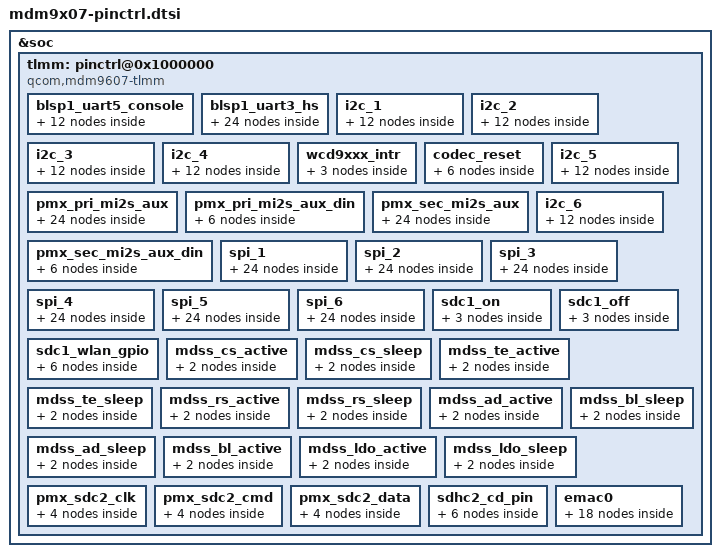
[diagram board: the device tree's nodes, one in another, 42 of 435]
&soc {
	tlmm: pinctrl@0x1000000 {
		compatible = "qcom,mdm9607-tlmm";
		reg = <0x1000000 0x300000>;
		reg-names = "pinctrl";
		interrupts = <0 208 IRQ_TYPE_LEVEL_HIGH>;
		gpio-controller;
		#gpio-cells = <2>;
		interrupt-controller;
		interrupt-parent = <&intc>;
		#interrupt-cells = <2>;
		wakeup-parent = <&wakegic>;

		blsp1_uart5_console: blsp1_uart5_console {
			blsp1_uart5_console_tx5_active: blsp1_uart5_console_tx5_active {
				mux {
					pins = "gpio8";
					function = "blsp_uart_tx5";
				};

				config {
					pins = "gpio8";
					drive-strength = <2>;
					bias-disable;
				};
			};

			blsp1_uart5_console_tx5_sleep: blsp1_uart5_console_tx5_sleep {
				mux {
					pins = "gpio8";
					function = "blsp_uart_tx5";
				};

				config {
					pins = "gpio8";
					drive-strength = <2>;
					bias-pull-up;
				};
			};

			blsp1_uart5_console_rx5_active: blsp1_uart5_console_rx5_active {
				mux {
					pins = "gpio9";
					function = "blsp_uart_rx5";
				};

				config {
					pins = "gpio9";
					drive-strength = <2>;
					bias-disable;
				};
			};

			blsp1_uart5_console_rx5_sleep: blsp1_uart5_console_rx5_sleep {
				mux {
					pins = "gpio9";
					function = "blsp_uart_rx5";
				};

				config {
					pins = "gpio9";
					drive-strength = <2>;
					bias-no-pull;
				};
			};
		};

		blsp1_uart3_hs: blsp1_uart3_hs {
			blsp1_uart3_hs_tx_active: blsp1_uart3_hs_tx_active {
				mux {
					pins = "gpio0";
					function = "blsp_uart_tx3";
				};

				config {
					pins = "gpio0";
					drive-strength = <2>;
					bias-pull-up;
				};
			};

			blsp1_uart3_hs_tx_sleep: blsp1_uart3_hs_tx_sleep {
				mux {
					pins = "gpio0";
					function = "blsp_uart_tx3";
				};

				config {
					pins = "gpio0";
					drive-strength = <2>;
					bias-pull-up;
				};
			};

			blsp1_uart3_hs_rx_active: blsp1_uart3_hs_rx_active {
				mux {
					pins = "gpio1";
					function = "blsp_uart_rx3";
				};

				config {
					pins = "gpio1";
					drive-strength = <2>;
					bias-disable;
				};
			};

			blsp1_uart3_hs_rx_sleep: blsp1_uart3_hs_rx_sleep {
				mux {
					pins = "gpio1";
					function = "gpio";
				};

				config {
					pins = "gpio1";
					drive-strength = <2>;
					bias-pull-down;
				};
			};

			blsp1_uart3_hs_cts_active: blsp1_uart3_hs_cts_active {
				mux {
					pins = "gpio2";
					function = "blsp_uart3";
				};

				config {
					pins = "gpio2";
					drive-strength = <2>;
					bias-disable;
				};
			};

			blsp1_uart3_hs_cts_sleep: blsp1_uart3_hs_cts_sleep {
				mux {
					pins = "gpio2";
					function = "blsp_uart3";
				};

				config {
					pins = "gpio2";
					drive-strength = <2>;
					bias-pull-down;
				};
			};

			blsp1_uart3_hs_rfr_active: blsp1_uart3_hs_rfr_active {
				mux {
					pins = "gpio3";
					function = "blsp_uart3";
				};

				config {
					pins = "gpio3";
					drive-strength = <2>;
					bias-pull-down;
				};
			};

			blsp1_uart3_hs_rfr_sleep: blsp1_uart3_hs_rfr_sleep {
				mux {
					pins = "gpio3";
					function = "blsp_uart3";
				};

				config {
					pins = "gpio3";
					drive-strength = <2>;
					bias-pull-down;
				};
			};
		};

		i2c_1 {
			i2c_1_sda1_active: i2c_1_sda1_active {
				mux {
					pins = "gpio14";
					function = "blsp_i2c_sda1";
				};

				config {
					pins = "gpio14";
					drive-strength = <2>;
					bias-pull-up;
				};
			};

			i2c_1_sda1_sleep: i2c_1_sda1_sleep {
				mux {
					pins = "gpio14";
					function = "blsp_i2c_sda1";
				};

				config {
					pins = "gpio14";
					drive-strength = <2>;
					bias-disable;
				};
			};

			i2c_1_scl1_active: i2c_1_scl1_active {
				mux {
					pins = "gpio15";
					function = "blsp_i2c_scl1";
				};

				config {
					pins = "gpio15";
					drive-strength = <2>;
					bias-pull-up;
				};
			};

			i2c_1_scl1_sleep: i2c_1_scl1_sleep {
				mux {
					pins = "gpio15";
					function = "blsp_i2c_scl1";
				};

				config {
					pins = "gpio15";
					drive-strength = <2>;
					bias-disable;
				};
			};
		};

		i2c_2 {
			i2c_2_sda2_active: i2c_2_sda2_active {
				mux {
					pins = "gpio6";
					function = "blsp_i2c_sda2";
				};

				config {
					pins = "gpio6";
					drive-strength = <2>;
					bias-pull-up;
				};
			};

			i2c_2_sda2_sleep: i2c_2_sda2_sleep {
				mux {
					pins = "gpio6";
					function = "blsp_i2c_sda2";
				};

				config {
					pins = "gpio6";
					drive-strength = <2>;
					bias-disable;
				};
			};

			i2c_2_scl2_active: i2c_2_scl2_active {
				mux {
					pins = "gpio7";
					function = "blsp_i2c_scl2";
				};

				config {
					pins = "gpio7";
					drive-strength = <2>;
					bias-pull-up;
				};
			};

			i2c_2_scl2_sleep: i2c_2_scl2_sleep {
				mux {
					pins = "gpio7";
					function = "blsp_i2c_scl2";
				};

				config {
					pins = "gpio7";
					drive-strength = <2>;
					bias-disable;
				};
			};
		};

		i2c_3 {
			i2c_3_sda3_active: i2c_3_sda3_active {
				mux {
					pins = "gpio2";
					function = "blsp_i2c_sda3";
				};

				config {
					pins = "gpio2";
					drive-strength = <2>;
					bias-pull-up;
				};
			};

			i2c_3_sda3_sleep: i2c_3_sda3_sleep {
				mux {
					pins = "gpio2";
					function = "blsp_i2c_sda3";
				};

				config {
					pins = "gpio2";
					drive-strength = <2>;
					bias-disable;
				};
			};

			i2c_3_scl3_active: i2c_3_scl3_active {
				mux {
					pins = "gpio3";
					function = "blsp_i2c_scl3";
				};

				config {
					pins = "gpio3";
					drive-strength = <2>;
					bias-pull-up;
				};
			};

			i2c_3_scl3_sleep: i2c_3_scl3_sleep {
				mux {
					pins = "gpio3";
					function = "blsp_i2c_scl3";
				};

				config {
					pins = "gpio3";
					drive-strength = <2>;
					bias-disable;
				};
			};
		};

		i2c_4 {
			i2c_4_sda4_active: i2c_4_sda4_active {
				mux {
					pins = "gpio18";
					function = "blsp_i2c_sda4";
				};

				config {
					pins = "gpio18";
					drive-strength = <2>;
					bias-pull-up;
				};
			};

			i2c_4_sda4_sleep: i2c_4_sda4_sleep {
				mux {
					pins = "gpio18";
					function = "blsp_i2c_sda4";
				};

				config {
					pins = "gpio18";
					drive-strength = <2>;
					bias-disable;
				};
			};

			i2c_4_scl4_active: i2c_4_scl4_active {
				mux {
					pins = "gpio19";
					function = "blsp_i2c_scl4";
				};

				config {
					pins = "gpio19";
					drive-strength = <2>;
					bias-pull-up;
				};
			};

			i2c_4_scl4_sleep: i2c_4_scl4_sleep {
				mux {
					pins = "gpio19";
					function = "blsp_i2c_scl4";
				};

				config {
					pins = "gpio19";
					drive-strength = <2>;
					bias-disable;
				};
			};
		};

		wcd9xxx_intr {
			wcd_intr_default: wcd_intr_default {
				mux {
					pins = "gpio75";
					function = "gpio";
				};

				config {
					pins = "gpio75";
					drive-strength = <2>; /* 2 mA */
					bias-pull-down; /* pull down */
					input-enable;
				};
			};
		};

		codec_reset {
			codec_reset_active: codec_reset_active {
				mux {
					pins = "gpio26";
					function = "gpio";
				};

				config {
					pins = "gpio26";
					drive-strength = <8>;   /* 8 MA */
					bias-disable;           /* No PULL */
					output-high;
				};
			};

			codec_reset_sleep: codec_reset_sleep {
				mux {
					pins = "gpio26";
					function = "gpio";
				};

				config {
					pins = "gpio26";
					drive-strength = <2>;   /* 2 MA */
					bias-pull-down;	        /* PULL DOWN */
				};
			};
		};

		pmx_pri_mi2s_aux {
			pri_ws_active_master: pri_ws_active_master {
				mux {
					pins = "gpio20";
					function = "pri_mi2s_ws_a";
				};

				config {
					pins = "gpio20";
					drive-strength = <8>;   /* 8 MA */
					bias-disable;           /* No PULL */
					output-high;
				};
			};

			pri_sck_active_master: pri_sck_active_master {
				mux {
					pins = "gpio23";
					function = "pri_mi2s_sck_a";
				};

				config {
					pins = "gpio23";
					drive-strength = <8>;   /* 8 MA */
					bias-disable;           /* No PULL */
					output-high;
				};
			};

			pri_ws_active_slave: pri_ws_active_slave {
				mux {
					pins = "gpio20";
					function = "pri_mi2s_ws_a";
				};

				config {
					pins = "gpio20";
					drive-strength = <8>;   /* 8 MA */
					bias-disable;           /* No PULL */
				};
			};

			pri_sck_active_slave: pri_sck_active_slave {
				mux {
					pins = "gpio23";
					function = "pri_mi2s_sck_a";
				};

				config {
					pins = "gpio23";
					drive-strength = <8>;   /* 8 MA */
					bias-disable;           /* No PULL */
				};
			};

			pri_dout_active: pri_dout_active {
				mux {
					pins = "gpio22";
					function = "pri_mi2s_data1_a";
				};

				config {
					pins = "gpio22";
					drive-strength = <8>;   /* 8 MA */
					bias-disable;           /* No PULL */
					output-high;
				};
			};

			pri_ws_sleep: pri_ws_sleep {
				mux {
					pins = "gpio20";
					function = "pri_mi2s_ws_a";
				};

				config {
					pins = "gpio20";
					drive-strength = <2>;   /* 2 MA */
					bias-pull-down;	        /* PULL DOWN */
				};
			};

			pri_sck_sleep: pri_sck_sleep {
				mux {
					pins = "gpio23";
					function = "pri_mi2s_sck_a";
				};

				config {
					pins = "gpio23";
					drive-strength = <2>;   /* 2 MA */
					bias-pull-down;	        /* PULL DOWN */
				};
			};

			pri_dout_sleep: pri_dout_sleep {
				mux {
					pins = "gpio22";
					function = "pri_mi2s_data1_a";
				};

				config {
					pins = "gpio22";
					drive-strength = <2>;   /* 2 MA */
					bias-pull-down;	        /* PULL DOWN */
				};
			};
		};

		pmx_pri_mi2s_aux_din {
				pri_din_active: pri_din_active {
				mux {
					pins = "gpio21";
					function = "pri_mi2s_data0_a";
				};

				config {
					pins = "gpio21";
					drive-strength = <8>;   /* 8 MA */
					bias-disable;	        /* No PULL */
				};
			};

			pri_din_sleep: pri_din_sleep {
				mux {
					pins = "gpio21";
					function = "pri_mi2s_data0_a";
				};

				config {
					pins = "gpio21";
					drive-strength = <2>;   /* 2 MA */
					bias-pull-down;	        /* PULL DOWN */
				};
			};
		};

		pmx_sec_mi2s_aux {
			sec_ws_active_master: sec_ws_active_master {
				mux {
					pins = "gpio79";
					function = "sec_mi2s_ws";
				};

				config {
					pins = "gpio79";
					drive-strength = <8>;   /* 8 MA */
					bias-disable;           /* No PULL */
					output-high;
				};
			};

			sec_sck_active_master: sec_sck_active_master {
				mux {
					pins = "gpio78";
					function = "sec_mi2s_sck";
				};

				config {
					pins = "gpio78";
					drive-strength = <8>;   /* 8 MA */
					bias-disable;           /* No PULL */
					output-high;
				};
			};

			sec_ws_active_slave: sec_ws_active_slave {
				mux {
					pins = "gpio79";
					function = "sec_mi2s_ws";
				};

				config {
					pins = "gpio79";
					drive-strength = <8>;   /* 8 MA */
					bias-disable;           /* No PULL */
				};
			};

			sec_sck_active_slave: sec_sck_active_slave {
				mux {
					pins = "gpio78";
					function = "sec_mi2s_sck";
				};

				config {
					pins = "gpio78";
					drive-strength = <8>;   /* 8 MA */
					bias-disable;           /* No PULL */
				};
			};

			sec_dout_active: sec_dout_active {
				mux {
					pins = "gpio77";
					function = "sec_mi2s_data1";
				};

				config {
					pins = "gpio77";
					drive-strength = <8>;   /* 8 MA */
					bias-disable;           /* No PULL */
					output-high;
				};
			};

			sec_ws_sleep: sec_ws_sleep {
				mux {
					pins = "gpio79";
					function = "sec_mi2s_ws";
				};

				config {
					pins = "gpio79";
					drive-strength = <2>;   /* 2 MA */
					bias-pull-down;	        /* PULL DOWN */
				};
			};

			sec_sck_sleep: sec_sck_sleep {
				mux {
					pins = "gpio78";
					function = "sec_mi2s_sck";
				};

				config {
					pins = "gpio78";
					drive-strength = <2>;   /* 2 MA */
					bias-pull-down;	        /* PULL DOWN */
				};
			};

			sec_dout_sleep: sec_dout_sleep {
				mux {
					pins = "gpio77";
					function = "sec_mi2s_data1";
				};

				config {
					pins = "gpio77";
					drive-strength = <2>;   /* 2 MA */
					bias-pull-down;	        /* PULL DOWN */
				};
			};
		};

		pmx_sec_mi2s_aux_din {
			sec_din_active: sec_din_active {
				mux {
					pins = "gpio76";
					function = "sec_mi2s_data0";
				};

				config {
					pins = "gpio76";
					drive-strength = <8>;   /* 8 MA */
					bias-disable;	        /* No PULL */
				};
			};

			sec_din_sleep: sec_din_sleep {
				mux {
					pins = "gpio76";
					function = "sec_mi2s_data0";
				};

				config {
					pins = "gpio76";
					drive-strength = <2>;   /* 2 MA */
					bias-pull-down;	        /* PULL DOWN */
				};
			};
		};

		i2c_5 {
			i2c_5_sda5_active: i2c_5_sda5_active {
				mux {
					pins = "gpio10";
					function = "blsp_i2c_sda5";
				};

				config {
					pins = "gpio10";
					drive-strength = <2>;
					bias-pull-up;
				};
			};

			i2c_5_sda5_sleep: i2c_5_sda5_sleep {
				mux {
					pins = "gpio10";
					function = "blsp_i2c_sda5";
				};

				config {
					pins = "gpio10";
					drive-strength = <2>;
					bias-disable;
				};
			};

			i2c_5_scl5_active: i2c_5_scl5_active {
				mux {
					pins = "gpio11";
					function = "blsp_i2c_scl5";
				};

				config {
					pins = "gpio11";
					drive-strength = <2>;
					bias-pull-up;
				};
			};

			i2c_5_scl5_sleep: i2c_5_scl5_sleep {
				mux {
					pins = "gpio11";
					function = "blsp_i2c_scl5";
				};

				config {
					pins = "gpio11";
					drive-strength = <2>;
					bias-disable;
				};
			};
		};

		i2c_6 {
			i2c_6_sda6_active: i2c_6_sda6_active {
				mux {
					pins = "gpio22";
					function = "blsp_i2c_sda6";
				};

				config {
					pins = "gpio22";
					drive-strength = <2>;
					bias-pull-up;
				};
			};

			i2c_6_sda6_sleep: i2c_6_sda6_sleep {
				mux {
					pins = "gpio22";
					function = "blsp_i2c_sda6";
				};

				config {
					pins = "gpio22";
					drive-strength = <2>;
					bias-disable;
				};
			};

			i2c_6_scl6_active: i2c_6_scl6_active {
				mux {
					pins = "gpio23";
					function = "blsp_i2c_scl6";
				};

				config {
					pins = "gpio23";
					drive-strength = <2>;
					bias-pull-up;
				};
			};

			i2c_6_scl6_sleep: i2c_6_scl6_sleep {
				mux {
					pins = "gpio23";
					function = "blsp_i2c_scl6";
				};

				config {
					pins = "gpio23";
					drive-strength = <2>;
					bias-disable;
				};
			};
		};

		spi_1 {
			spi_1_mosi1_default: spi_1_mosi1_default {
				mux {
					pins = "gpio12";
					function = "blsp_spi_mosi1";
				};

				config {
					pins = "gpio12";
					drive-strength = <12>;
					bias-disable;
				};
			};

			spi_1_mosi1_sleep: spi_1_mosi1_sleep {
				mux {
					pins = "gpio12";
					function = "blsp_spi_mosi1";
				};

				config {
					pins = "gpio12";
					drive-strength = <2>;
					bias-pull-down;
				};
			};

			spi_1_miso1_default: spi_1_miso1_default {
				mux {
					pins = "gpio13";
					function = "blsp_spi_miso1";
				};

				config {
					pins = "gpio13";
					drive-strength = <12>;
					bias-disable;
				};
			};

			spi_1_miso1_sleep: spi_1_miso1_sleep {
				mux {
					pins = "gpio13";
					function = "blsp_spi_miso1";
				};

				config {
					pins = "gpio13";
					drive-strength = <2>;
					bias-pull-down;
				};
			};

			spi_1_cs1_active: spi_1_cs1_active {
				mux {
					pins = "gpio14";
					function = "blsp_spi1";
				};

				config {
					pins = "gpio14";
					drive-strength = <2>;
					bias-disable;
				};
			};

			spi_1_cs1_sleep: spi_1_cs1_sleep {
				mux {
					pins = "gpio14";
					function = "blsp_spi1";
				};

				config {
					pins = "gpio14";
					drive-strength = <2>;
					bias-pull-down;
				};
			};

			spi_1_clk1_default: spi_1_clk1_default {
				mux {
					pins = "gpio15";
					function = "blsp_spi_clk1";
				};

				config {
					pins = "gpio15";
					drive-strength = <12>;
					bias-disable;
				};
			};

			spi_1_clk1_sleep: spi_1_clk1_sleep {
				mux {
					pins = "gpio15";
					function = "blsp_spi_clk1";
				};

				config {
					pins = "gpio15";
					drive-strength = <2>;
					bias-pull-down;
				};
			};
		};

		spi_2 {
			spi_2_mosi2_default: spi_2_mosi2_default {
				mux {
					pins = "gpio4";
					function = "blsp_spi_mosi2";
				};

				config {
					pins = "gpio4";
					drive-strength = <12>;
					bias-disable;
				};
			};

			spi_2_mosi2_sleep: spi_2_mosi2_sleep {
				mux {
					pins = "gpio4";
					function = "blsp_spi_mosi2";
				};

				config {
					pins = "gpio4";
					drive-strength = <2>;
					bias-pull-down;
				};
			};

			spi_2_miso2_default: spi_2_miso2_default {
				mux {
					pins = "gpio5";
					function = "blsp_spi_miso2";
				};

				config {
					pins = "gpio5";
					drive-strength = <12>;
					bias-disable;
				};
			};

			spi_2_miso2_sleep: spi_2_miso2_sleep {
				mux {
					pins = "gpio5";
					function = "blsp_spi_miso2";
				};

				config {
					pins = "gpio5";
					drive-strength = <2>;
					bias-pull-down;
				};
			};

			spi_2_cs2_active: spi_2_cs2_active {
				mux {
					pins = "gpio6";
					function = "blsp_spi2";
				};

				config {
					pins = "gpio6";
					drive-strength = <2>;
					bias-disable;
				};
			};

			spi_2_cs2_sleep: spi_2_cs2_sleep {
				mux {
					pins = "gpio6";
					function = "blsp_spi2";
				};

				config {
					pins = "gpio6";
					drive-strength = <2>;
					bias-pull-down;
				};
			};

			spi_2_clk2_default: spi_2_clk2_default {
				mux {
					pins = "gpio7";
					function = "blsp_spi_clk2";
				};

				config {
					pins = "gpio7";
					drive-strength = <12>;
					bias-disable;
				};
			};

			spi_2_clk2_sleep: spi_2_clk2_sleep {
				mux {
					pins = "gpio7";
					function = "blsp_spi_clk2";
				};

				config {
					pins = "gpio7";
					drive-strength = <2>;
					bias-pull-down;
				};
			};
		};

		spi_3 {
			spi_3_mosi3_default: spi_3_mosi3_default {
				mux {
					pins = "gpio0";
					function = "blsp_spi_mosi3";
				};

				config {
					pins = "gpio0";
					drive-strength = <12>;
					bias-disable;
				};
			};

			spi_3_mosi3_sleep: spi_3_mosi3_sleep {
				mux {
					pins = "gpio0";
					function = "blsp_spi_mosi3";
				};

				config {
					pins = "gpio0";
					drive-strength = <2>;
					bias-pull-down;
				};
			};

			spi_3_miso3_default: spi_3_miso3_default {
				mux {
					pins = "gpio1";
					function = "blsp_spi_miso3";
				};

				config {
					pins = "gpio1";
					drive-strength = <12>;
					bias-disable;
				};
			};

			spi_3_miso3_sleep: spi_3_miso3_sleep {
				mux {
					pins = "gpio1";
					function = "blsp_spi_miso3";
				};

				config {
					pins = "gpio1";
					drive-strength = <2>;
					bias-pull-down;
				};
			};

			spi_3_cs3_active: spi_3_cs3_active {
				mux {
					pins = "gpio2";
					function = "blsp_spi3";
				};

				config {
					pins = "gpio2";
					drive-strength = <2>;
					bias-disable;
				};
			};

			spi_3_cs3_sleep: spi_3_cs3_sleep {
				mux {
					pins = "gpio2";
					function = "blsp_spi3";
				};

				config {
					pins = "gpio2";
					drive-strength = <2>;
					bias-pull-down;
				};
			};

			spi_3_clk3_default: spi_3_clk3_default {
				mux {
					pins = "gpio3";
					function = "blsp_spi_clk3";
				};

				config {
					pins = "gpio3";
					drive-strength = <12>;
					bias-disable;
				};
			};

			spi_3_clk3_sleep: spi_3_clk3_sleep {
				mux {
					pins = "gpio3";
					function = "blsp_spi_clk3";
				};

				config {
					pins = "gpio3";
					drive-strength = <2>;
					bias-pull-down;
				};
			};
		};

		spi_4 {
			spi_4_mosi4_default: spi_4_mosi4_default {
				mux {
					pins = "gpio16";
					function = "blsp_spi_mosi4";
				};

				config {
					pins = "gpio16";
					drive-strength = <12>;
					bias-disable;
				};
			};

			spi_4_mosi4_sleep: spi_4_mosi4_sleep {
				mux {
					pins = "gpio16";
					function = "blsp_spi_mosi4";
				};

				config {
					pins = "gpio16";
					drive-strength = <2>;
					bias-pull-down;
				};
			};

			spi_4_miso4_default: spi_4_miso4_default {
				mux {
					pins = "gpio17";
					function = "blsp_spi_miso4";
				};

				config {
					pins = "gpio17";
					drive-strength = <12>;
					bias-disable;
				};
			};

			spi_4_miso4_sleep: spi_4_miso4_sleep {
				mux {
					pins = "gpio17";
					function = "blsp_spi_miso4";
				};

				config {
					pins = "gpio17";
					drive-strength = <2>;
					bias-pull-down;
				};
			};

			spi_4_cs4_active: spi_4_cs4_active {
				mux {
					pins = "gpio18";
					function = "blsp_spi4";
				};

				config {
					pins = "gpio18";
					drive-strength = <2>;
					bias-disable;
				};
			};

			spi_4_cs4_sleep: spi_4_cs4_sleep {
				mux {
					pins = "gpio18";
					function = "blsp_spi4";
				};

				config {
					pins = "gpio18";
					drive-strength = <2>;
					bias-pull-down;
				};
			};

			spi_4_clk4_default: spi_4_clk4_default {
				mux {
					pins = "gpio19";
					function = "blsp_spi_clk4";
				};

				config {
					pins = "gpio19";
					drive-strength = <12>;
					bias-disable;
				};
			};

			spi_4_clk4_sleep: spi_4_clk4_sleep {
				mux {
					pins = "gpio19";
					function = "blsp_spi_clk4";
				};

				config {
					pins = "gpio19";
					drive-strength = <2>;
					bias-pull-down;
				};
			};
		};

		spi_5 {
			spi_5_mosi5_default: spi_5_mosi5_default {
				mux {
					pins = "gpio8";
					function = "blsp_spi_mosi5";
				};

				config {
					pins = "gpio8";
					drive-strength = <12>;
					bias-disable;
				};
			};

			spi_5_mosi5_sleep: spi_5_mosi5_sleep {
				mux {
					pins = "gpio8";
					function = "blsp_spi_mosi5";
				};

				config {
					pins = "gpio8";
					drive-strength = <2>;
					bias-pull-down;
				};
			};

			spi_5_miso5_default: spi_5_miso5_default {
				mux {
					pins = "gpio9";
					function = "blsp_spi_miso5";
				};

				config {
					pins = "gpio9";
					drive-strength = <12>;
					bias-disable;
				};
			};

			spi_5_miso5_sleep: spi_5_miso5_sleep {
				mux {
					pins = "gpio9";
					function = "blsp_spi_miso5";
				};

				config {
					pins = "gpio9";
					drive-strength = <2>;
					bias-pull-down;
				};
			};

			spi_5_cs5_active: spi_5_cs5_active {
				mux {
					pins = "gpio10";
					function = "blsp_spi5";
				};

				config {
					pins = "gpio10";
					drive-strength = <2>;
					bias-disable;
				};
			};

			spi_5_cs5_sleep: spi_5_cs5_sleep {
				mux {
					pins = "gpio10";
					function = "blsp_spi5";
				};

				config {
					pins = "gpio10";
					drive-strength = <2>;
					bias-pull-down;
				};
			};

			spi_5_clk5_default: spi_5_clk5_default {
				mux {
					pins = "gpio11";
					function = "blsp_spi_clk5";
				};

				config {
					pins = "gpio11";
					drive-strength = <12>;
					bias-disable;
				};
			};

			spi_5_clk5_sleep: spi_5_clk5_sleep {
				mux {
					pins = "gpio11";
					function = "blsp_spi_clk5";
				};

				config {
					pins = "gpio11";
					drive-strength = <2>;
					bias-pull-down;
				};
			};
		};

		spi_6 {
			spi_6_mosi6_default: spi_6_mosi6_default {
				mux {
					pins = "gpio20";
					function = "blsp_spi_mosi6";
				};

				config {
					pins = "gpio20";
					drive-strength = <12>;
					bias-disable;
				};
			};

			spi_6_mosi6_sleep: spi_6_mosi6_sleep {
				mux {
					pins = "gpio20";
					function = "blsp_spi_mosi6";
				};

				config {
					pins = "gpio20";
					drive-strength = <2>;
					bias-pull-down;
				};
			};

			spi_6_miso6_default: spi_6_miso6_default {
				mux {
					pins = "gpio21";
					function = "blsp_spi_miso6";
				};

				config {
					pins = "gpio21";
					drive-strength = <12>;
					bias-disable;
				};
			};

			spi_6_miso6_sleep: spi_6_miso6_sleep {
				mux {
					pins = "gpio21";
					function = "blsp_spi_miso6";
				};

				config {
					pins = "gpio21";
					drive-strength = <2>;
					bias-pull-down;
				};
			};

			spi_6_cs6_active: spi_6_cs6_active {
				mux {
					pins = "gpio22";
					function = "blsp_spi6";
				};

				config {
					pins = "gpio22";
					drive-strength = <2>;
					bias-disable;
				};
			};

			spi_6_cs6_sleep: spi_6_cs6_sleep {
				mux {
					pins = "gpio22";
					function = "blsp_spi6";
				};

				config {
					pins = "gpio22";
					drive-strength = <2>;
					bias-pull-down;
				};
			};

			spi_6_clk6_default: spi_6_clk6_default {
				mux {
					pins = "gpio23";
					function = "blsp_spi_clk6";
				};

				config {
					pins = "gpio23";
					drive-strength = <12>;
					bias-disable;
				};
			};

			spi_6_clk6_sleep: spi_6_clk6_sleep {
				mux {
					pins = "gpio23";
					function = "blsp_spi_clk6";
				};

				config {
					pins = "gpio23";
					drive-strength = <2>;
					bias-pull-down;
				};
			};
		};

		/* SDC pin type */


		sdc1_on: sdc1_on {
			clk {
				pins = "sdc1_clk";
				bias-disable;
				drive-strength = <16>;
			};

			cmd {
				pins = "sdc1_cmd";
				bias-pull-up;
				drive-strength = <10>;
			};

			data {
				pins = "sdc1_data";
				bias-pull-up;
				drive-strength = <10>;
			};
		};

		sdc1_off: sdc1_off {
			clk {
				pins = "sdc1_clk";
				bias-disable;
				drive-strength = <2>;
			};

			cmd {
				pins = "sdc1_cmd";
				bias-pull-up;
				drive-strength = <2>;
			};

			data {
				pins = "sdc1_data";
				bias-pull-up;
				drive-strength = <2>;
			};
		};

		sdc1_wlan_gpio {
			sdc1_wlan_gpio_active: sdc1_wlan_gpio_active {
				mux {
					pins = "gpio38";
					function  = "gpio";
				};

				config {
					pins  = "gpio38";
					output-high;
					drive-strength = <8>;
					bias-pull-up;
				};
			};

			sdc1_wlan_gpio_sleep: sdc1_wlan_gpio_sleep {
				mux {
					pins = "gpio38";
					function  = "gpio";
				};

				config {
					pins  = "gpio38";
					drive-strength = <2>;
					bias-disable;
					output-low;
				};
			};
		};

		mdss_cs_active: mdss_cs_active {
			mux {
				pins = "gpio23";
				function = "ebi2_lcd_cs_n_b";
			};

			config {
				pins = "gpio23";
				drive-strength = <10>;/*10mA*/
				bias-disable;/*NOpull*/
			};
		};

		mdss_cs_sleep:mdss_cs_sleep {
			mux {
				pins = "gpio23";
				function = "ebi2_lcd_cs_n_b";
			};

			config {
				pins = "gpio23";
				drive-strength = <2>;/*2mA*/
				bias-disable;/*NOpull*/
			};
		};

		mdss_te_active:mdss_te_active {
			mux {
				pins = "gpio20";
				function = "ebi2_lcd_te_b";
			};

			config {
				pins = "gpio20";
				drive-strength = <10>;/*10mA*/
				bias-disable;/*NOpull*/
			};
		};

		mdss_te_sleep:mdss_te_sleep {
			mux {
				pins = "gpio20";
				function = "ebi2_lcd_te_b";
			};

			config {
				pins = "gpio20";
				drive-strength = <2>;/*2mA*/
				bias-disable;/*NOpull*/
			};
		};

		mdss_rs_active:mdss_rs_active {
			mux {
				pins = "gpio74";
				function = "ebi2_lcd";
			};

			config {
				pins = "gpio74";
				drive-strength = <10>;/*10mA*/
				bias-disable;/*NOpull*/
			};
		};

		mdss_rs_sleep:mdss_rs_sleep {
			mux {
				pins = "gpio74";
				function = "ebi2_lcd";
			};

			config {
				pins = "gpio74";
				drive-strength = <2>;/*2mA*/
				bias-disable;/*NOpull*/
			};
		};

		mdss_ad_active:mdss_ad_active {
			mux {
				pins = "gpio22";
				function = "ebi2_a_d_8_b";
			};

			config {
				pins = "gpio22";
				drive-strength = <10>;/*10mA*/
				bias-disable;/*NOpull*/
			};
		};

		mdss_ad_sleep:mdss_ad_sleep {
			mux {
				pins = "gpio22";
				function = "ebi2_a_d_8_b";
			};

			config {
				pins = "gpio22";
				drive-strength = <2>;/*2mA*/
				bias-disable;/*NOpull*/
			};
		};

		mdss_bl_active:mdss_bl_active {
			mux {
				pins = "gpio21";
				function = "gpio";
			};

			config {
				pins = "gpio21";
				drive-strength = <10>;/*10mA*/
				bias-disable;/*NOpull*/
				output-high;
			};
		};

		mdss_bl_sleep:mdss_bl_sleep {
			mux {
				pins = "gpio21";
				function = "gpio";
			};

			config {
				pins = "gpio21";
				drive-strength = <2>;/*2mA*/
				bias-disable;/*NOpull*/
			};
		};

		mdss_ldo_active:mdss_ldo_active {
			mux {
				pins = "gpio10";
				function = "gpio";
			};

			config {
				pins = "gpio10";
				drive-strength = <10>;/*10mA*/
				bias-disable;/*NOpull*/
				output-high;
			};
		};

		mdss_ldo_sleep:mdss_ldo_sleep {
			mux {
				pins = "gpio10";
				function = "gpio";
			};

			config {
				pins = "gpio10";
				drive-strength = <2>;/*2mA*/
				bias-disable;/*NOpull*/
				output-low;
			};
		};

		pmx_sdc2_clk {
			sdc2_clk_on: sdc2_clk_on {
				config {
					pins = "sdc2_clk";
					drive-strength = <16>; /* 16 MA */
					bias-disable; /* NO pull */
				};
			};

			sdc2_clk_off: sdc2_clk_off {
				config {
					pins = "sdc2_clk";
					bias-disable; /* NO pull */
					drive-strength = <2>; /* 2 MA */
				};
			};
		};

		pmx_sdc2_cmd {
			sdc2_cmd_on: sdc2_cmd_on {
				config {
					pins = "sdc2_cmd";
					bias-pull-up; /* pull up */
					drive-strength = <10>; /* 10 MA */
				};
			};

			sdc2_cmd_off: sdc2_cmd_off {
				config {
					pins = "sdc2_cmd";
					bias-pull-up; /* pull up */
					drive-strength = <2>; /* 2 MA */
				};
			};
		};

		pmx_sdc2_data {
			sdc2_data_on: sdc2_data_on {
				config {
					pins = "sdc2_data";
					bias-pull-up; /* pull up */
					drive-strength = <10>; /* 10 MA */
				};
			};

			sdc2_data_off: sdc2_data_off {
				config {
					pins = "sdc2_data";
					bias-pull-up; /* pull up */
					drive-strength = <2>; /* 2 MA */
				};
			};
		};

		sdhc2_cd_pin {
			sdc2_cd_on: cd_on {
				mux {
					pins = "gpio26";
					function = "gpio";
				};

				config {
					pins = "gpio26";
					drive-strength = <2>;
					bias-pull-up;
				};
			};

			sdc2_cd_off: cd_off {
				mux {
					pins = "gpio26";
					function = "gpio";
				};

				config {
					pins = "gpio26";
					drive-strength = <2>;
					bias-disable;
				};
			};
		};

		emac0 {
			emac0_mdio_clk_active: emac0_mdio_clk_active {
				/* active state */
				mux {
					/* MDC MDIO */
					pins = "gpio27";
					function = "gmac_mdio_clk";
				};

				config {
					pins = "gpio27";
					drive-strength = <16>; /* 16 MA */
					bias-pull-up;
				};
			};

			emac0_mdio_clk_sleep: emac0_mdio_clk_sleep {
				/* suspended state */
				mux {
					/* MDC MDIO */
					pins = "gpio27";
					function = "gpio";
				};

				config {
					pins = "gpio27";
					drive-strength = <2>; /* 2 MA */
					bias-pull-down;
				};
			};

			emac0_mdio_data_active: emac0_mdio_data_active {
				/* active state */
				mux {
					/* MDC MDIO */
					pins = "gpio28";
					function = "gmac_mdio_data";
				};

				config {
					pins = "gpio28";
					drive-strength = <16>; /* 16 MA */
					bias-pull-up;
				};
			};

			emac0_mdio_data_sleep: emac0_mdio_data_sleep {
				/* suspended state */
				mux {
					/* MDC MDIO */
					pins = "gpio28";
					function = "gpio";
				};

				config {
					pins = "gpio28";
					drive-strength = <2>; /* 2 MA */
					bias-pull-down;
				};
			};

			emac0_ephy_active: emac0_ephy_active {
				/* active state */
				mux {
					/* EPHY RST */
					pins = "gpio29";
					function = "gpio";
				};

				config {
					pins = "gpio29";
					drive-strength = <16>; /* 16 MA */
					bias-pull-up;
					output-high;
				};
			};

			emac0_ephy_sleep: emac0_ephy_sleep {
				/* suspended state */
				mux {
					/* EPHY RST */
					pins = "gpio29";
					function = "gpio";
				};

				config {
					pins = "gpio29";
					drive-strength = <2>; /* 2 MA */
					bias-disable;
					output-low;
				};
			};
		};
	};
};
